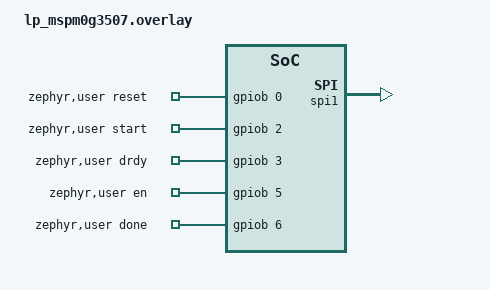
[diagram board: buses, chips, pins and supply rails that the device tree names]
  #include <zephyr/dt-bindings/gpio/gpio.h>


/ {
	  aliases {
		  spi-1 = &spi1;
	  };

	  zephyr,user {
		  reset-gpios = <&gpiob 0 GPIO_ACTIVE_HIGH>;
		  start-gpios = <&gpiob 2 GPIO_ACTIVE_HIGH>;
		  drdy-gpios  = <&gpiob 3 GPIO_ACTIVE_HIGH>;
		  en-gpios    = <&gpiob 5 GPIO_ACTIVE_HIGH>;
		  done-gpios  = <&gpiob 6 GPIO_ACTIVE_HIGH>;
	  };

  };

  &spi1 {
	  //pinctrl-0 = <&spi1_sclk_pa17 &spi1_pico_pb15 &spi1_poci_pb21 &spi1_cs0_pb20>;
	  //pinctrl-names = "default";
	  //cs-gpios = <&gpiob 20 GPIO_ACTIVE_LOW>;
	  status = "okay";
  };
